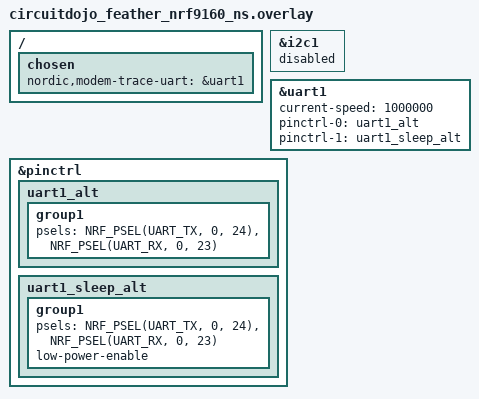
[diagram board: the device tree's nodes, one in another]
/ {
	chosen {
		nordic,modem-trace-uart = &uart1;
	};
}; 

&i2c1 {
	status = "disabled";
};

&uart1 {
	current-speed = <1000000>;
	pinctrl-0 = <&uart1_alt>;
	pinctrl-1 = <&uart1_sleep_alt>;
	pinctrl-names = "default", "sleep";
};

&pinctrl {
	uart1_alt: uart1_alt {
		group1 {
			psels = <NRF_PSEL(UART_TX, 0, 24)>,
				<NRF_PSEL(UART_RX, 0, 23)>;
		};
	};

	uart1_sleep_alt: uart1_sleep_alt {
		group1 {
			psels = <NRF_PSEL(UART_TX, 0, 24)>,
				<NRF_PSEL(UART_RX, 0, 23)>;
			low-power-enable;
		};
	};
};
